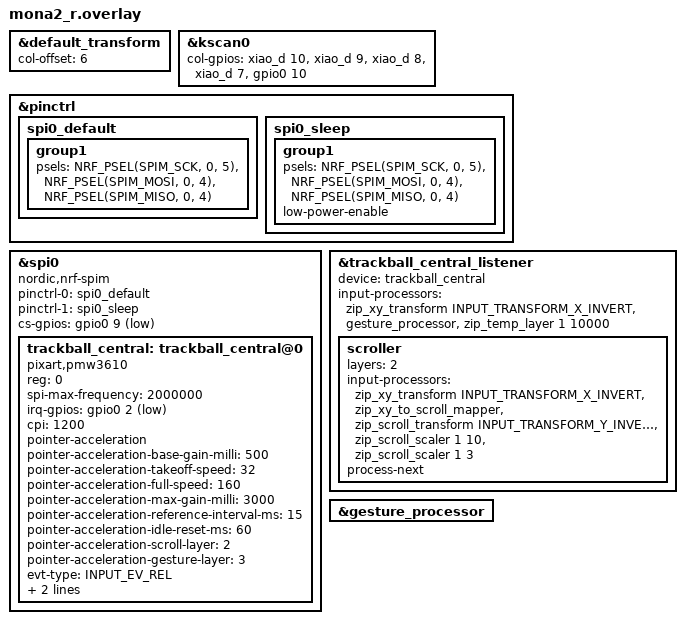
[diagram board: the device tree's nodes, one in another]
#include "mona2.dtsi"
#include <input/processors.dtsi>
#include <zephyr/dt-bindings/input/input-event-codes.h>


&default_transform {
    col-offset = <6>;
};

&kscan0 {
        col-gpios
            = <&xiao_d 10 GPIO_ACTIVE_HIGH>
            , <&xiao_d 9 GPIO_ACTIVE_HIGH> 
            , <&xiao_d 8 GPIO_ACTIVE_HIGH> 
            , <&xiao_d 7 GPIO_ACTIVE_HIGH> 
            , <&gpio0 10 GPIO_ACTIVE_HIGH>
            ;
};


&pinctrl {
    spi0_default: spi0_default {    //通常時(SPI通信中)のピン構成
        group1 {
            psels = <NRF_PSEL(SPIM_SCK, 0, 5)>, //P0.05を指定(SCLK)
                <NRF_PSEL(SPIM_MOSI, 0, 4)>,    //P0.04を指定(SDIOだからMOSI,MISO両方の役割を担う)
                <NRF_PSEL(SPIM_MISO, 0, 4)>;
        };
    };

    spi0_sleep: spi0_sleep {    //スリープ時のピン構成(省電力)
        group1 {
            psels = <NRF_PSEL(SPIM_SCK, 0, 5)>,
                <NRF_PSEL(SPIM_MOSI, 0, 4)>,
                <NRF_PSEL(SPIM_MISO, 0, 4)>;
            low-power-enable;
        };
    };
};


&spi0 {
    status = "okay";
    compatible = "nordic,nrf-spim"; //マイコンがnRFシリーズ
    pinctrl-0 = <&spi0_default>;
    pinctrl-1 = <&spi0_sleep>;
    pinctrl-names = "default", "sleep";
    cs-gpios = <&gpio0 9 GPIO_ACTIVE_LOW>;  //P0.09を指定(CS)

    trackball_central: trackball_central@0 {
        status = "okay";
        compatible = "pixart,pmw3610";  //トラボセンサ用のドライバとバインド
        reg = <0>;
        spi-max-frequency = <2000000>;
        irq-gpios = <&gpio0 2 (GPIO_ACTIVE_LOW | GPIO_PULL_UP)>; //P0.02を指定(MOTION)
        cpi = <1200>;
        pointer-acceleration;
        pointer-acceleration-base-gain-milli = <500>;
        pointer-acceleration-takeoff-speed = <32>;
        pointer-acceleration-full-speed = <160>;
        pointer-acceleration-max-gain-milli = <3000>;
        pointer-acceleration-reference-interval-ms = <15>;
        pointer-acceleration-idle-reset-ms = <60>;
        pointer-acceleration-scroll-layer = <2>;
        pointer-acceleration-gesture-layer = <3>;
        // Keep sensor-axis flags disabled. Pointer and Gesture direction is
        // normalized once by the listener; Scroll uses its separate chain.
        //swap-xy;
        //invert-x;
        //invert-y;
        evt-type = <INPUT_EV_REL>;
        x-input-code = <INPUT_REL_X>;
        y-input-code = <INPUT_REL_Y>;
    };
};


// Overrides for the input listener node
&trackball_central_listener {
    status = "okay";
    device = <&trackball_central>;

    input-processors =
        <&zip_xy_transform INPUT_TRANSFORM_X_INVERT>,
        <&gesture_processor>,
        <&zip_temp_layer 1 10000>;

    scroller {
        layers = <2>;
        // Reverse both outputs from the accepted 17b4108 candidate. The
        // pre-mapper X inversion plus post-mapper Y inversion flips both.
        input-processors = 
            // <&zip_xy_transform INPUT_TRANSFORM_XY_SWAP>,        //X軸とY軸の入れ替え
            <&zip_xy_transform INPUT_TRANSFORM_X_INVERT>,       //X軸反転
            <&zip_xy_to_scroll_mapper>,                         //スクロールモードに変更
            <&zip_scroll_transform INPUT_TRANSFORM_Y_INVERT>,
            <&zip_scroll_scaler 1 10>,                         //既存スケール
            <&zip_scroll_scaler 1 3>;                          //実機調整: 合計1/30
        process-next;
    };

};

&gesture_processor {
    status = "okay";
};
